# BL702 register map
Vendor: Bouffalo Lab; Series: WiFi BT; File version: 1.0
Registers are 32-bit, read-write, reset 0x0 unless marked. A register's access mark holds for its fields unless they carry their own. Offsets are from the block's base; [hi:lo] are bit positions; {n}, {i} and the like mark numbered series.

## AON
Base 0x4000F000
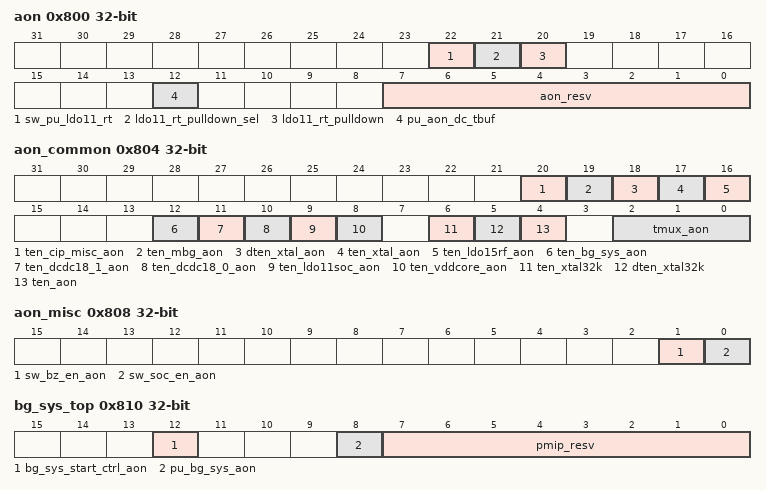
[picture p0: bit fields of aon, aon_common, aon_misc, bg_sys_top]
0x800 aon
  [22] sw_pu_ldo11_rt, [21] ldo11_rt_pulldown_sel, [20] ldo11_rt_pulldown, [12] pu_aon_dc_tbuf, [7:0] aon_resv
0x804 aon_common
  [20] ten_cip_misc_aon, [19] ten_mbg_aon, [18] dten_xtal_aon, [17] ten_xtal_aon, [16] ten_ldo15rf_aon, [12] ten_bg_sys_aon, [11] ten_dcdc18_1_aon, [10] ten_dcdc18_0_aon, [9] ten_ldo11soc_aon, [8] ten_vddcore_aon, [6] ten_xtal32k, [5] dten_xtal32k, [4] ten_aon, [2:0] tmux_aon
0x808 aon_misc
  [1] sw_bz_en_aon, [0] sw_soc_en_aon
0x810 bg_sys_top
  [12] bg_sys_start_ctrl_aon, [8] pu_bg_sys_aon, [7:0] pmip_resv
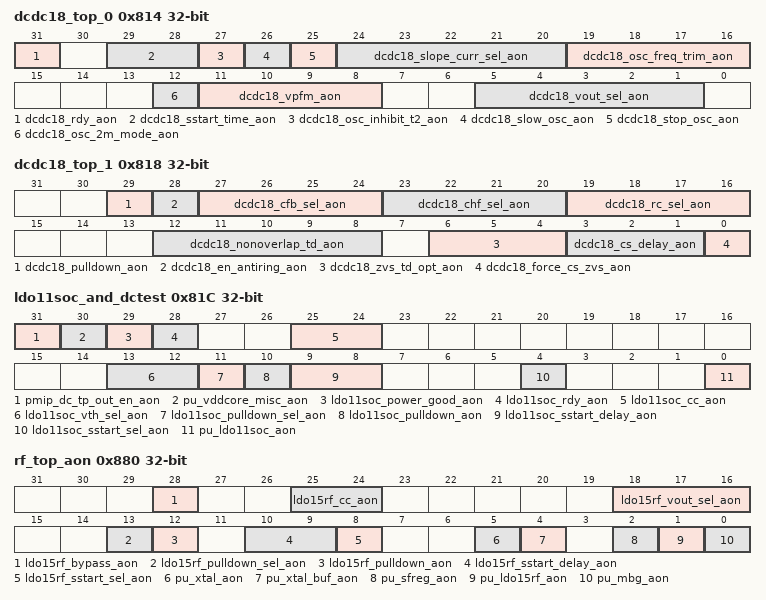
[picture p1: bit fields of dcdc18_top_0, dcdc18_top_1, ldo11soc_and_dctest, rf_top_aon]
0x814 dcdc18_top_0
  [31] dcdc18_rdy_aon, [29:28] dcdc18_sstart_time_aon, [27] dcdc18_osc_inhibit_t2_aon, [26] dcdc18_slow_osc_aon, [25] dcdc18_stop_osc_aon, [24:20] dcdc18_slope_curr_sel_aon, [19:16] dcdc18_osc_freq_trim_aon, [12] dcdc18_osc_2m_mode_aon, [11:8] dcdc18_vpfm_aon, [5:1] dcdc18_vout_sel_aon
0x818 dcdc18_top_1
  [29] dcdc18_pulldown_aon, [28] dcdc18_en_antiring_aon, [27:24] dcdc18_cfb_sel_aon, [23:20] dcdc18_chf_sel_aon, [19:16] dcdc18_rc_sel_aon, [12:8] dcdc18_nonoverlap_td_aon, [6:4] dcdc18_zvs_td_opt_aon, [3:1] dcdc18_cs_delay_aon, [0] dcdc18_force_cs_zvs_aon
0x81C ldo11soc_and_dctest
  [31] pmip_dc_tp_out_en_aon, [30] pu_vddcore_misc_aon, [29] ldo11soc_power_good_aon, [28] ldo11soc_rdy_aon, [25:24] ldo11soc_cc_aon, [13:12] ldo11soc_vth_sel_aon, [11] ldo11soc_pulldown_sel_aon, [10] ldo11soc_pulldown_aon, [9:8] ldo11soc_sstart_delay_aon, [4] ldo11soc_sstart_sel_aon, [0] pu_ldo11soc_aon
0x820 psw_irrcv
  [0] pu_ir_psw_aon
0x880 rf_top_aon
  [28] ldo15rf_bypass_aon, [25:24] ldo15rf_cc_aon, [18:16] ldo15rf_vout_sel_aon, [13] ldo15rf_pulldown_sel_aon, [12] ldo15rf_pulldown_aon, [10:9] ldo15rf_sstart_delay_aon, [8] ldo15rf_sstart_sel_aon, [5] pu_xtal_aon, [4] pu_xtal_buf_aon, [2] pu_sfreg_aon, [1] pu_ldo15rf_aon, [0] pu_mbg_aon
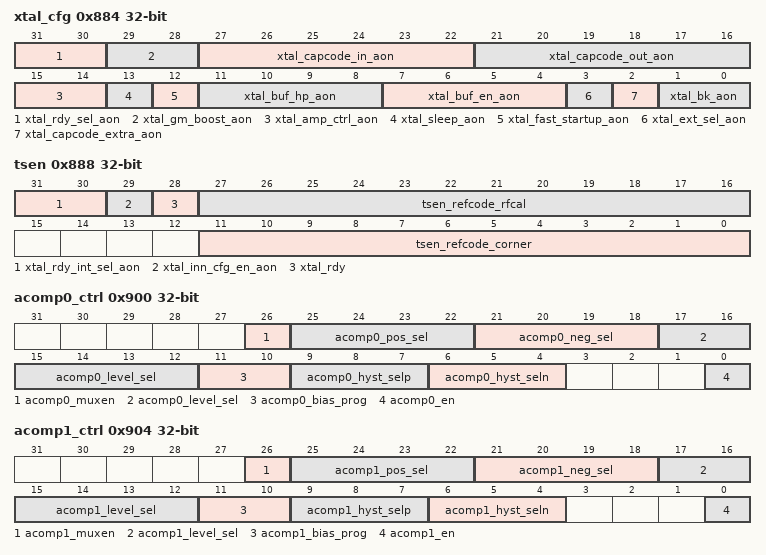
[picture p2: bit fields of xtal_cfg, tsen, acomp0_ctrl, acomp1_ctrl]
0x884 xtal_cfg
  [31:30] xtal_rdy_sel_aon, [29:28] xtal_gm_boost_aon, [27:22] xtal_capcode_in_aon, [21:16] xtal_capcode_out_aon, [15:14] xtal_amp_ctrl_aon, [13] xtal_sleep_aon, [12] xtal_fast_startup_aon, [11:8] xtal_buf_hp_aon, [7:4] xtal_buf_en_aon, [3] xtal_ext_sel_aon, [2] xtal_capcode_extra_aon, [1:0] xtal_bk_aon
0x888 tsen
  [31:30] xtal_rdy_int_sel_aon, [29] xtal_inn_cfg_en_aon, [28] xtal_rdy, [27:16] tsen_refcode_rfcal, [11:0] tsen_refcode_corner
0x900 acomp0_ctrl
  [26] acomp0_muxen, [25:22] acomp0_pos_sel, [21:18] acomp0_neg_sel, [17:12] acomp0_level_sel, [11:10] acomp0_bias_prog, [9:7] acomp0_hyst_selp, [6:4] acomp0_hyst_seln, [0] acomp0_en
0x904 acomp1_ctrl
  [26] acomp1_muxen, [25:22] acomp1_pos_sel, [21:18] acomp1_neg_sel, [17:12] acomp1_level_sel, [11:10] acomp1_bias_prog, [9:7] acomp1_hyst_selp, [6:4] acomp1_hyst_seln, [0] acomp1_en
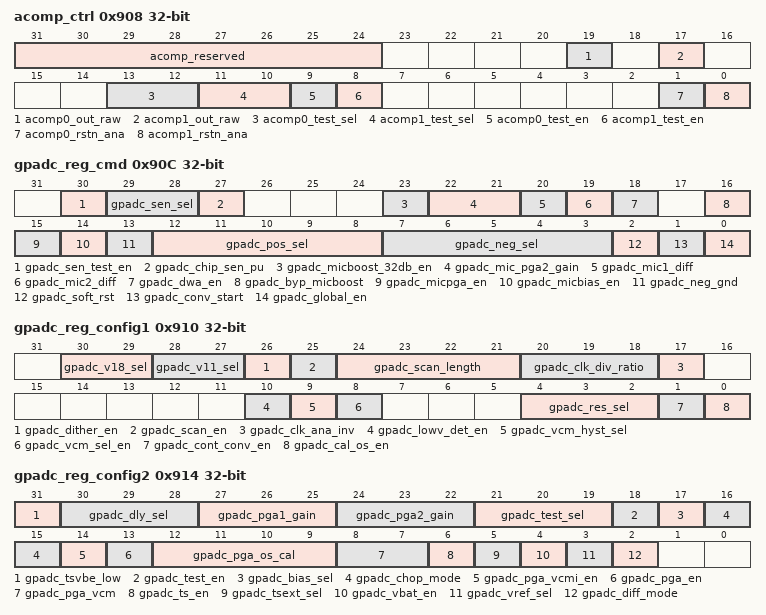
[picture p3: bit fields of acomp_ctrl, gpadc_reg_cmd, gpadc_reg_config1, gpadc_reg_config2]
0x908 acomp_ctrl
  [31:24] acomp_reserved, [19] acomp0_out_raw, [17] acomp1_out_raw, [13:12] acomp0_test_sel, [11:10] acomp1_test_sel, [9] acomp0_test_en, [8] acomp1_test_en, [1] acomp0_rstn_ana, [0] acomp1_rstn_ana
0x90C gpadc_reg_cmd
  [30] gpadc_sen_test_en, [29:28] gpadc_sen_sel, [27] gpadc_chip_sen_pu, [23] gpadc_micboost_32db_en, [22:21] gpadc_mic_pga2_gain, [20] gpadc_mic1_diff, [19] gpadc_mic2_diff, [18] gpadc_dwa_en, [16] gpadc_byp_micboost, [15] gpadc_micpga_en, [14] gpadc_micbias_en, [13] gpadc_neg_gnd, [12:8] gpadc_pos_sel, [7:3] gpadc_neg_sel, [2] gpadc_soft_rst, [1] gpadc_conv_start, [0] gpadc_global_en
0x910 gpadc_reg_config1
  [30:29] gpadc_v18_sel, [28:27] gpadc_v11_sel, [26] gpadc_dither_en, [25] gpadc_scan_en, [24:21] gpadc_scan_length, [20:18] gpadc_clk_div_ratio, [17] gpadc_clk_ana_inv, [10] gpadc_lowv_det_en, [9] gpadc_vcm_hyst_sel, [8] gpadc_vcm_sel_en, [4:2] gpadc_res_sel, [1] gpadc_cont_conv_en, [0] gpadc_cal_os_en
0x914 gpadc_reg_config2
  [31] gpadc_tsvbe_low, [30:28] gpadc_dly_sel, [27:25] gpadc_pga1_gain, [24:22] gpadc_pga2_gain, [21:19] gpadc_test_sel, [18] gpadc_test_en, [17] gpadc_bias_sel, [16:15] gpadc_chop_mode, [14] gpadc_pga_vcmi_en, [13] gpadc_pga_en, [12:9] gpadc_pga_os_cal, [8:7] gpadc_pga_vcm, [6] gpadc_ts_en, [5] gpadc_tsext_sel, [4] gpadc_vbat_en, [3] gpadc_vref_sel, [2] gpadc_diff_mode
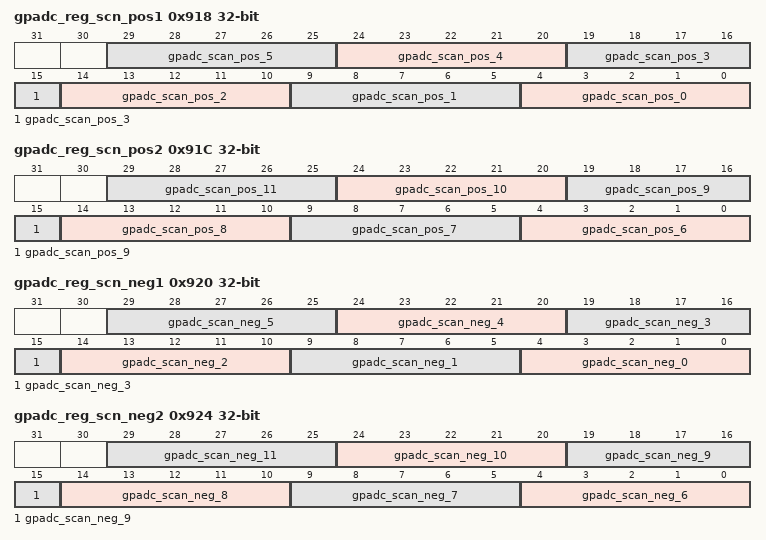
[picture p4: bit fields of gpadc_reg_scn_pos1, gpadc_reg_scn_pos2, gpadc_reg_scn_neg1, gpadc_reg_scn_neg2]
0x918 gpadc_reg_scn_pos1 — adc converation sequence 1
  [5n+4:5n] gpadc_scan_pos_{n} (n=0..5)
0x91C gpadc_reg_scn_pos2 — adc converation sequence 2
  [5n-26:5n-30] gpadc_scan_pos_{n} (n=6..11)
0x920 gpadc_reg_scn_neg1 — adc converation sequence 3
  [5n+4:5n] gpadc_scan_neg_{n} (n=0..5)
0x924 gpadc_reg_scn_neg2 — adc converation sequence 4
  [5n-26:5n-30] gpadc_scan_neg_{n} (n=6..11)
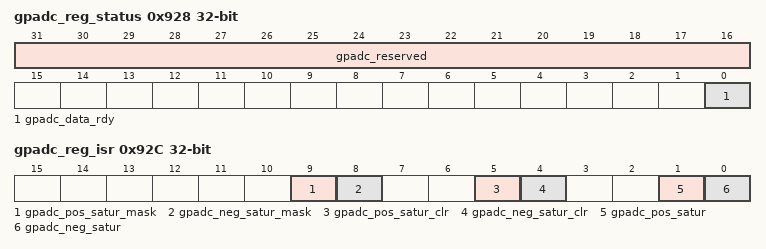
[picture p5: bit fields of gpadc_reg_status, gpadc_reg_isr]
0x928 gpadc_reg_status
  [31:16] gpadc_reserved, [0] gpadc_data_rdy
0x92C gpadc_reg_isr
  [9] gpadc_pos_satur_mask, [8] gpadc_neg_satur_mask, [5] gpadc_pos_satur_clr, [4] gpadc_neg_satur_clr, [1] gpadc_pos_satur, [0] gpadc_neg_satur
0x930 gpadc_reg_result
  [25:0] gpadc_data_out
0x934 gpadc_reg_raw_result
  [11:0] gpadc_raw_data
0x938 gpadc_reg_define
  [15:0] gpadc_os_cal_data
0x93C hbncore_resv0
  [31:0] hbncore_resv0_data
0x940 hbncore_resv1
  [31:0] hbncore_resv1_data
